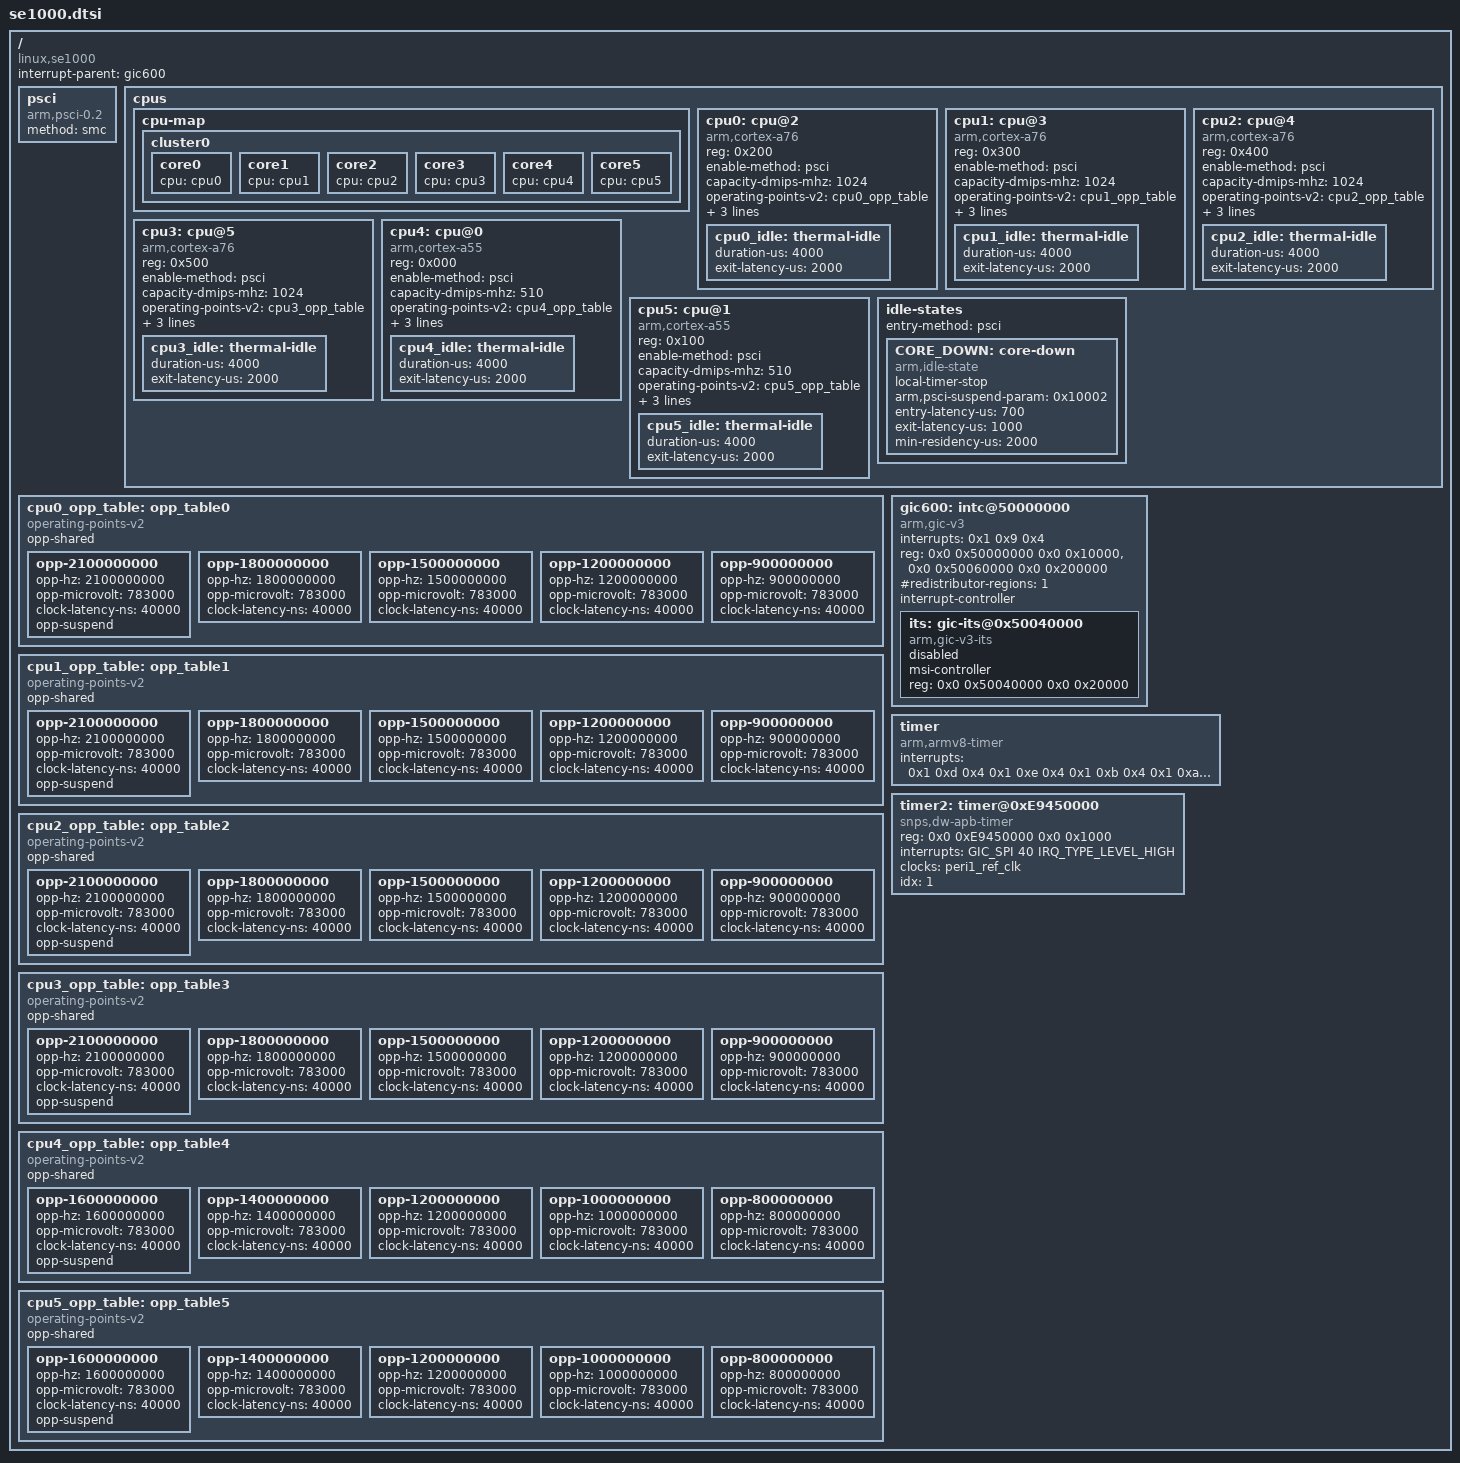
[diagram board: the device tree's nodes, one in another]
// SPDX-License-Identifier: GPL-2.0
/*
 * dts file for Siengine SE1000 SoC
 *
 * Copyright (C) 2022, siengine Ltd.
 */

#include <dt-bindings/interrupt-controller/arm-gic.h>
#include "dt-bindings/clock/se1000-clock.h"
#include "se1000_clock.dtsi"
#include "dt-bindings/rpmsg/siengine-rpmsg-id.h"

/ {
	compatible = "linux,se1000";
	interrupt-parent = <&gic600>;
	#size-cells = <0x2>;
	#address-cells = <0x2>;

	psci {
		method = "smc";
		compatible = "arm,psci-0.2", "arm,psci";
	};

	cpus {
		#size-cells = <0x0>;
		#address-cells = <0x1>;

		cpu-map {
			cluster0 {
				core0 {
					cpu = <&cpu0>;
				};
				core1 {
					cpu = <&cpu1>;
				};
				core2 {
					cpu = <&cpu2>;
				};
				core3 {
					cpu = <&cpu3>;
				};
				core4 {
					cpu = <&cpu4>;
				};
				core5 {
					cpu = <&cpu5>;
				};
			};
		};

		cpu0: cpu@2 {
			reg = <0x200>;
			enable-method = "psci";
			compatible = "arm,cortex-a76";
			device_type = "cpu";
			capacity-dmips-mhz = <1024>;
			operating-points-v2 = <&cpu0_opp_table>;
			#cooling-cells = <2>;
			dynamic-power-coefficient = <478>;
			cpu-idle-states =<&CORE_DOWN>;
			clocks = <&crg_clk STEP_AP0_CLK_CORE2>;
			clock-names = "cpu";

			cpu0_idle: thermal-idle {
				#cooling-cells = <2>;
				duration-us = <4000>;
				exit-latency-us = <2000>;
			};
		};

		cpu1: cpu@3 {
			reg = <0x300>;
			enable-method = "psci";
			compatible = "arm,cortex-a76";
			device_type = "cpu";
			capacity-dmips-mhz = <1024>;
			operating-points-v2 = <&cpu1_opp_table>;
			#cooling-cells = <2>;
			dynamic-power-coefficient = <478>;
			cpu-idle-states = <&CORE_DOWN>;
			clocks = <&crg_clk STEP_AP0_CLK_CORE3>;
			clock-names = "cpu";

			cpu1_idle: thermal-idle {
				#cooling-cells = <2>;
				duration-us = <4000>;
				exit-latency-us = <2000>;
			};
		};

		cpu2: cpu@4 {
			reg = <0x400>;
			enable-method = "psci";
			compatible = "arm,cortex-a76";
			device_type = "cpu";
			capacity-dmips-mhz = <1024>;
			operating-points-v2 = <&cpu2_opp_table>;
			#cooling-cells = <2>;
			dynamic-power-coefficient = <478>;
			cpu-idle-states = <&CORE_DOWN>;
			clocks = <&crg_clk STEP_AP0_CLK_CORE4>;
			clock-names = "cpu";

			cpu2_idle: thermal-idle {
				#cooling-cells = <2>;
				duration-us = <4000>;
				exit-latency-us = <2000>;
			};
		};

		cpu3: cpu@5 {
			reg = <0x500>;
			enable-method = "psci";
			compatible = "arm,cortex-a76";
			device_type = "cpu";
			capacity-dmips-mhz = <1024>;
			operating-points-v2 = <&cpu3_opp_table>;
			#cooling-cells = <2>;
			dynamic-power-coefficient = <478>;
			cpu-idle-states = <&CORE_DOWN>;
			clocks = <&crg_clk STEP_AP0_CLK_CORE5>;
			clock-names = "cpu";

			cpu3_idle: thermal-idle {
				#cooling-cells = <2>;
				duration-us = <4000>;
				exit-latency-us = <2000>;
			};
		};

		cpu4: cpu@0 {
			reg = <0x000>;
			enable-method = "psci";
			compatible = "arm,cortex-a55";
			device_type = "cpu";
			capacity-dmips-mhz = <510>;
			operating-points-v2 = <&cpu4_opp_table>;
			#cooling-cells = <2>;
			dynamic-power-coefficient = <154>;
			cpu-idle-states = <&CORE_DOWN>;
			clocks = <&crg_clk STEP_AP0_CLK_CORE0>;
			clock-names = "cpu";

			cpu4_idle: thermal-idle {
				#cooling-cells = <2>;
				duration-us = <4000>;
				exit-latency-us = <2000>;
			};
		};

		cpu5: cpu@1 {
			reg = <0x100>;
			enable-method = "psci";
			compatible = "arm,cortex-a55";
			device_type = "cpu";
			capacity-dmips-mhz = <510>;
			operating-points-v2 = <&cpu5_opp_table>;
			#cooling-cells = <2>;
			dynamic-power-coefficient = <154>;
			cpu-idle-states = <&CORE_DOWN>;
			clocks = <&crg_clk STEP_AP0_CLK_CORE1>;
			clock-names = "cpu";

			cpu5_idle: thermal-idle {
				#cooling-cells = <2>;
				duration-us = <4000>;
				exit-latency-us = <2000>;
			};
		};

		idle-states {
			entry-method = "psci";
#if 0
			CPU_SLEEP: cpu-sleep {
				compatible = "arm,idle-state";
				local-timer-stop;
				arm,psci-suspend-param = <0x1>;
				entry-latency-us = <700>;
				exit-latency-us = <250>;
				min-residency-us = <1000>;
			};
#endif
			CORE_DOWN: core-down {
				compatible = "arm,idle-state";
				local-timer-stop;
				arm,psci-suspend-param = <0x10002>;
				entry-latency-us = <700>;
				exit-latency-us = <1000>;
				min-residency-us = <2000>;
			};
		};

	};


	cpu0_opp_table: opp_table0 {
		compatible = "operating-points-v2";
		opp-shared;

		opp-2100000000 {
			opp-hz = /bits/ 64 <2100000000>;
			opp-microvolt = <783000>;
			clock-latency-ns = <40000>;
			opp-suspend;
		};

		opp-1800000000 {
			opp-hz = /bits/ 64 <1800000000>;
			opp-microvolt = <783000>;
			clock-latency-ns = <40000>;
		};

		opp-1500000000 {
			opp-hz = /bits/ 64 <1500000000>;
			opp-microvolt = <783000>;
			clock-latency-ns = <40000>;
		};

		opp-1200000000 {
			opp-hz = /bits/ 64 <1200000000>;
			opp-microvolt = <783000>;
			clock-latency-ns = <40000>;
		};

		opp-900000000 {
			opp-hz = /bits/ 64 <900000000>;
			opp-microvolt = <783000>;
			clock-latency-ns = <40000>;
		};
	};

	cpu1_opp_table: opp_table1 {
		compatible = "operating-points-v2";
		opp-shared;

		opp-2100000000 {
			opp-hz = /bits/ 64 <2100000000>;
			opp-microvolt = <783000>;
			clock-latency-ns = <40000>;
			opp-suspend;
		};

		opp-1800000000 {
			opp-hz = /bits/ 64 <1800000000>;
			opp-microvolt = <783000>;
			clock-latency-ns = <40000>;
		};

		opp-1500000000 {
			opp-hz = /bits/ 64 <1500000000>;
			opp-microvolt = <783000>;
			clock-latency-ns = <40000>;
		};

		opp-1200000000 {
			opp-hz = /bits/ 64 <1200000000>;
			opp-microvolt = <783000>;
			clock-latency-ns = <40000>;
		};

		opp-900000000 {
			opp-hz = /bits/ 64 <900000000>;
			opp-microvolt = <783000>;
			clock-latency-ns = <40000>;
		};

	};

	cpu2_opp_table: opp_table2 {
		compatible = "operating-points-v2";
		opp-shared;

		opp-2100000000 {
			opp-hz = /bits/ 64 <2100000000>;
			opp-microvolt = <783000>;
			clock-latency-ns = <40000>;
			opp-suspend;
		};

		opp-1800000000 {
			opp-hz = /bits/ 64 <1800000000>;
			opp-microvolt = <783000>;
			clock-latency-ns = <40000>;
		};

		opp-1500000000 {
			opp-hz = /bits/ 64 <1500000000>;
			opp-microvolt = <783000>;
			clock-latency-ns = <40000>;
		};

		opp-1200000000 {
			opp-hz = /bits/ 64 <1200000000>;
			opp-microvolt = <783000>;
			clock-latency-ns = <40000>;
		};

		opp-900000000 {
			opp-hz = /bits/ 64 <900000000>;
			opp-microvolt = <783000>;
			clock-latency-ns = <40000>;
		};
	};

	cpu3_opp_table: opp_table3 {
		compatible = "operating-points-v2";
		opp-shared;

		opp-2100000000 {
			opp-hz = /bits/ 64 <2100000000>;
			opp-microvolt = <783000>;
			clock-latency-ns = <40000>;
			opp-suspend;
		};

		opp-1800000000 {
			opp-hz = /bits/ 64 <1800000000>;
			opp-microvolt = <783000>;
			clock-latency-ns = <40000>;
		};

		opp-1500000000 {
			opp-hz = /bits/ 64 <1500000000>;
			opp-microvolt = <783000>;
			clock-latency-ns = <40000>;
		};

		opp-1200000000 {
			opp-hz = /bits/ 64 <1200000000>;
			opp-microvolt = <783000>;
			clock-latency-ns = <40000>;
		};

		opp-900000000 {
			opp-hz = /bits/ 64 <900000000>;
			opp-microvolt = <783000>;
			clock-latency-ns = <40000>;
		};
	};

	cpu4_opp_table: opp_table4 {
		compatible = "operating-points-v2";
		opp-shared;

		opp-1600000000 {
			opp-hz = /bits/ 64 <1600000000>;
			opp-microvolt = <783000>;
			clock-latency-ns = <40000>;
			opp-suspend;
		};

		opp-1400000000 {
			opp-hz = /bits/ 64 <1400000000>;
			opp-microvolt = <783000>;
			clock-latency-ns = <40000>;
		};

		opp-1200000000 {
			opp-hz = /bits/ 64 <1200000000>;
			opp-microvolt = <783000>;
			clock-latency-ns = <40000>;
		};

		opp-1000000000 {
			opp-hz = /bits/ 64 <1000000000>;
			opp-microvolt = <783000>;
			clock-latency-ns = <40000>;
		};

		opp-800000000 {
			opp-hz = /bits/ 64 <800000000>;
			opp-microvolt = <783000>;
			clock-latency-ns = <40000>;
		};
	};

	cpu5_opp_table: opp_table5 {
		compatible = "operating-points-v2";
		opp-shared;

		opp-1600000000 {
			opp-hz = /bits/ 64 <1600000000>;
			opp-microvolt = <783000>;
			clock-latency-ns = <40000>;
			opp-suspend;
		};

		opp-1400000000 {
			opp-hz = /bits/ 64 <1400000000>;
			opp-microvolt = <783000>;
			clock-latency-ns = <40000>;
		};

		opp-1200000000 {
			opp-hz = /bits/ 64 <1200000000>;
			opp-microvolt = <783000>;
			clock-latency-ns = <40000>;
		};

		opp-1000000000 {
			opp-hz = /bits/ 64 <1000000000>;
			opp-microvolt = <783000>;
			clock-latency-ns = <40000>;
		};

		opp-800000000 {
			opp-hz = /bits/ 64 <800000000>;
			opp-microvolt = <783000>;
			clock-latency-ns = <40000>;
		};
	};

	gic600: intc@50000000 {
		compatible = "arm,gic-v3";
		interrupts = <0x1 0x9 0x4>;
		reg = <0x0 0x50000000 0x0 0x10000>, /* GICD */
		      <0x0 0x50060000 0x0 0x200000>; /* GICR */
		#redistributor-regions = <1>;
		ranges;
		#size-cells = <0x2>;
		#address-cells = <0x2>;
		interrupt-controller;
		#interrupt-cells = <0x3>;

		its: gic-its@0x50040000 {
			compatible = "arm,gic-v3-its";
			msi-controller;
			reg = <0x0 0x50040000 0x0 0x20000>;
			status = "disabled";
		};
	};

	timer {
		compatible = "arm,armv8-timer", "arm,armv7-timer";
		interrupts = <0x1 0xd 0x4 0x1 0xe 0x4 0x1 0xb 0x4 0x1 0xa 0x4>;
//		always-on;
	};
	timer2: timer@0xE9450000 {
		compatible = "snps,dw-apb-timer";
		reg = <0x0 0xE9450000 0x0 0x1000>;
		interrupts = <GIC_SPI 40 IRQ_TYPE_LEVEL_HIGH>;
		clocks = <&peri1_ref_clk>;
		clock-names = "timer";
		idx = <1>;
	};
};
